# STM32WB35_CM4 register map
File version: 1.3-IAR
CPU: CM4 r0p1, little endian, MPU, FPU, 4 interrupt priority bits
Registers are 32-bit, read-write, reset 0x0 unless marked. A register's access mark holds for its fields unless they carry their own. Offsets are from the block's base; [hi:lo] are bit positions; {n}, {i} and the like mark numbered series.

## PWR — Power control
Base 0x58000400
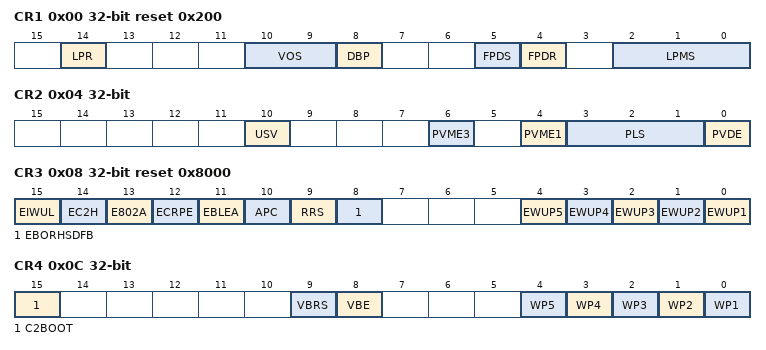
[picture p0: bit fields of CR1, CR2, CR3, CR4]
0x00 CR1 reset 0x200 — Power control register 1
  [14] LPR — Low-power run
  [10:9] VOS — Voltage scaling range selection
  [8] DBP — Disable backup domain write protection
  [5] FPDS — Flash power down mode during LPsSleep for CPU1
  [4] FPDR — Flash power down mode during LPRun for CPU1
  [2:0] LPMS — Low-power mode selection for CPU1
0x04 CR2 — Power control register 2
  [10] USV — VDDUSB USB supply valid
  [6] PVME3 — Peripheral voltage monitoring 3 enable: VDDA vs. 1.62V
  [4] PVME1 — Peripheral voltage monitoring 1 enable: VDDUSB vs. 1.2V
  [3:1] PLS — Power voltage detector level selection
  [0] PVDE — Power voltage detector enable
0x08 CR3 reset 0x8000 — Power control register 3
  [15] EIWUL — Enable internal wakeup line for CPU1
  [14] EC2H — Enable CPU2 Hold interrupt for CPU1
  [13] E802A — Enable end of activity interrupt for CPU1
  [12] ECRPE — Enable critical radio phase end of activity interrupt for CPU1
  [11] EBLEA — Enable BLE end of activity interrupt for CPU1
  [10] APC — Apply pull-up and pull-down configuration
  [9] RRS — SRAM2a retention in Standby mode
  [8] EBORHSDFB — Enable BORH and Step Down counverter forced in Bypass interrups for CPU1
  [n-1] EWUP{n} (n=1..5) — Enable Wakeup pin WKUP{n}
0x0C CR4 — Power control register 4
  [15] C2BOOT — BOOT CPU2 after reset or wakeup from Stop or Standby modes
  [9] VBRS — VBAT battery charging resistor selection
  [8] VBE — VBAT battery charging enable
  [n-1] WP{n} (n=1..5) — Wakeup pin WKUP{n} polarity
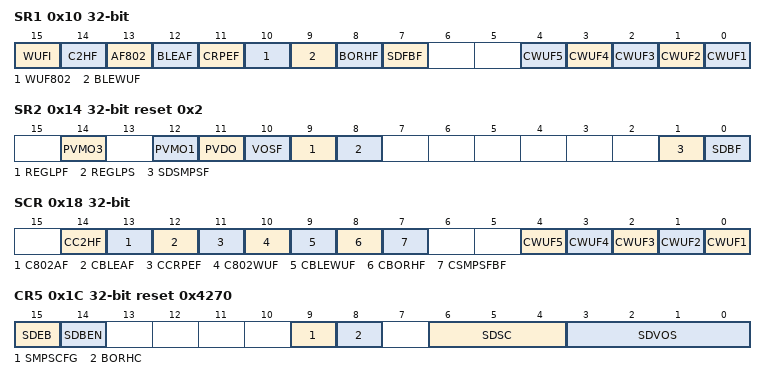
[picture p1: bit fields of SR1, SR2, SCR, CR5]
0x10 SR1 ro — Power status register 1
  [15] WUFI — Internal Wakeup interrupt flag
  [14] C2HF — CPU2 Hold interrupt flag
  [13] AF802 — 802.15.4 end of activity interrupt flag
  [12] BLEAF — BLE end of activity interrupt flag
  [11] CRPEF — Enable critical radio phase end of activity interrupt flag
  [10] WUF802 — 802.15.4 wakeup interrupt flag
  [9] BLEWUF — BLE wakeup interrupt flag
  [8] BORHF — BORH interrupt flag
  [7] SDFBF — Step Down converter forced in Bypass interrupt flag
  [n-1] CWUF{n} (n=1..5) — Wakeup flag {n}
0x14 SR2 ro reset 0x2 — Power status register 2
  [14] PVMO3 — Peripheral voltage monitoring output: VDDA vs. 1.62 V
  [12] PVMO1 — Peripheral voltage monitoring output: VDDUSB vs. 1.2 V
  [11] PVDO — Power voltage detector output
  [10] VOSF — Voltage scaling flag
  [9] REGLPF — Low-power regulator flag
  [8] REGLPS — Low-power regulator started
  [1] SDSMPSF — Step Down converter SMPS mode flag
  [0] SDBF — Step Down converter Bypass mode flag
0x18 SCR wo — Power status clear register
  [14] CC2HF — Clear CPU2 Hold interrupt flag
  [13] C802AF — Clear 802.15.4 end of activity interrupt flag
  [12] CBLEAF — Clear BLE end of activity interrupt flag
  [11] CCRPEF — Clear critical radio phase end of activity interrupt flag
  [10] C802WUF — Clear 802.15.4 wakeup interrupt flag
  [9] CBLEWUF — Clear BLE wakeup interrupt flag
  [8] CBORHF — Clear BORH interrupt flag
  [7] CSMPSFBF — Clear SMPS Step Down converter forced in Bypass interrupt flag
  [n-1] CWUF{n} (n=1..5) — Clear wakeup flag {n}
0x1C CR5 reset 0x4270 — Power control register 5
  [15] SDEB — Enable Step Down converter SMPS mode enabled
  [14] SDBEN — Enable Step Down converter Bypass mode enabled
  [9] SMPSCFG — VOS configuration selection (non user)
  [8] BORHC — BORH configuration selection
  [6:4] SDSC — Step Down converter supplt startup current selection
  [3:0] SDVOS — Step Down converter voltage output scaling
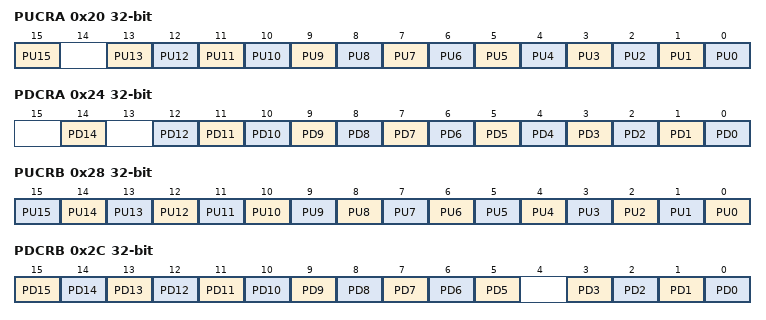
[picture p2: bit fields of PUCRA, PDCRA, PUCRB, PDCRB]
0x20 PUCRA — Power Port A pull-up control register
  [15] PU15 — Port A pull-up bit y (y=0..15)
  [n] PU{n} (n=0..13) — Port A pull-up bit y (y=0..15)
0x24 PDCRA — Power Port A pull-down control register
  [14] PD14 — Port A pull-down bit y (y=0..15)
  [n] PD{n} (n=0..12) — Port A pull-down bit y (y=0..15)
0x28 PUCRB — Power Port B pull-up control register
  [n] PU{n} (n=0..15) — Port B pull-up bit y (y=0..15)
0x2C PDCRB — Power Port B pull-down control register
  [n] PD{n} (n=5..15) — Port B pull-down bit y (y=0..15)
  [n] PD{n} (n=0..3) — Port B pull-down bit y (y=0..15)
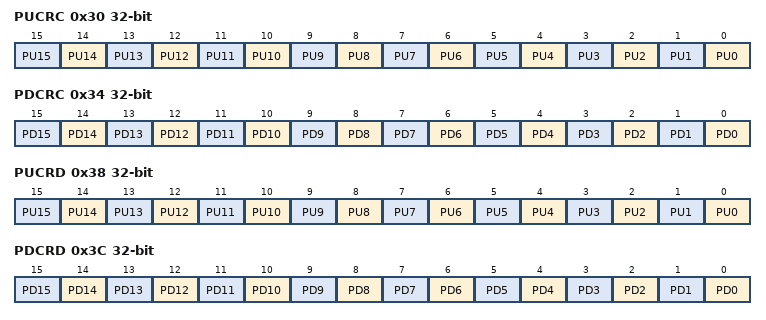
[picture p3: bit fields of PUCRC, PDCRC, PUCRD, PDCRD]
0x30 PUCRC — Power Port C pull-up control register
  [n] PU{n} (n=0..15) — Port C pull-up bit y (y=0..15)
0x34 PDCRC — Power Port C pull-down control register
  [n] PD{n} (n=0..15) — Port C pull-down bit y (y=0..15)
0x38 PUCRD — Power Port D pull-up control register
  [n] PU{n} (n=0..15) — Port D pull-up bit y (y=0..15)
0x3C PDCRD — Power Port D pull-down control register
  [n] PD{n} (n=0..15) — Port D pull-down bit y (y=0..15)
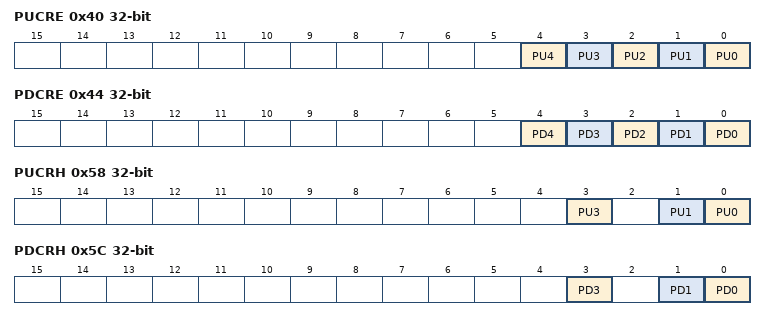
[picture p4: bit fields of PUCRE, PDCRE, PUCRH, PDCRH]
0x40 PUCRE — Power Port E pull-up control register
  [n] PU{n} (n=0..4) — Port E pull-up bit y (y=0..15)
0x44 PDCRE — Power Port E pull-down control register
  [n] PD{n} (n=0..4) — Port E pull-down bit y (y=0..15)
0x58 PUCRH — Power Port H pull-up control register
  [3] PU3 — Port H pull-up bit y (y=0..1)
  [1] PU1 — Port H pull-up bit y (y=0..1)
  [0] PU0 — Port H pull-up bit y (y=0..1)
0x5C PDCRH — Power Port H pull-down control register
  [3] PD3 — Port H pull-down bit y (y=0..1)
  [1] PD1 — Port H pull-down bit y (y=0..1)
  [0] PD0 — Port H pull-down bit y (y=0..1)
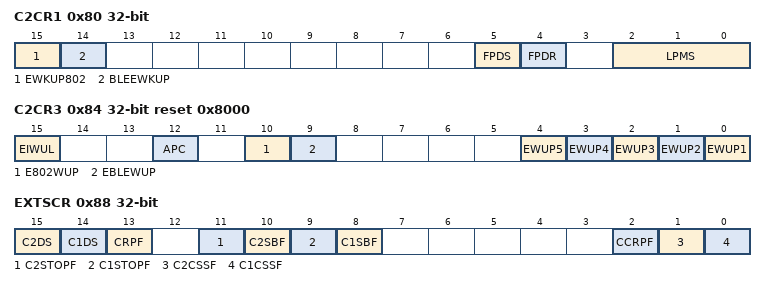
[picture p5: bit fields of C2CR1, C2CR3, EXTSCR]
0x80 C2CR1 — CPU2 Power control register 1
  [15] EWKUP802 — 802.15.4 external wakeup signal
  [14] BLEEWKUP — BLE external wakeup signal
  [5] FPDS — Flash power down mode during LPSleep for CPU2
  [4] FPDR — Flash power down mode during LPRun for CPU2
  [2:0] LPMS — Low-power mode selection for CPU2
0x84 C2CR3 reset 0x8000 — CPU2 Power control register 3
  [15] EIWUL — Enable internal wakeup line for CPU2
  [12] APC — Apply pull-up and pull-down configuration for CPU2
  [10] E802WUP — Enable 802.15.4 host wakeup interrupt for CPU2
  [9] EBLEWUP — Enable BLE host wakeup interrupt for CPU2
  [n-1] EWUP{n} (n=1..5) — Enable Wakeup pin WKUP{n} for CPU2
0x88 EXTSCR access per field — Power status clear register
  [15] C2DS ro — CPU2 deepsleep mode
  [14] C1DS ro — CPU1 deepsleep mode
  [13] CRPF ro — Critical Radio system phase
  [11] C2STOPF ro — System Stop flag for CPU2
  [10] C2SBF ro — System Standby flag for CPU2
  [9] C1STOPF ro — System Stop flag for CPU1
  [8] C1SBF ro — System Standby flag for CPU1
  [2] CCRPF wo — Clear Critical Radio system phase
  [1] C2CSSF wo — Clear CPU2 Stop Standby flags
  [0] C1CSSF wo — Clear CPU1 Stop Standby flags
